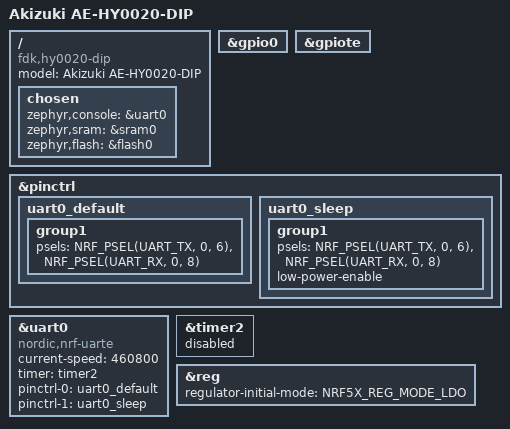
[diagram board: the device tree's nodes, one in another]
/dts-v1/;
#include <nordic/nrf52832_ciaa.dtsi>
#include <zephyr/dt-bindings/pinctrl/nrf-pinctrl.h>

/ {
    model = "Akizuki AE-HY0020-DIP";
    compatible = "fdk,hy0020-dip";

    chosen {
        zephyr,console = &uart0;
        zephyr,sram = &sram0;
        zephyr,flash = &flash0;
    };
};

&gpio0 {
    status = "okay";
};

&gpiote {
    status = "okay";
};

&pinctrl {
    uart0_default: uart0_default {
        group1 {
            psels = <NRF_PSEL(UART_TX, 0, 6)>, <NRF_PSEL(UART_RX, 0, 8)>;
        };
    };
    uart0_sleep: uart0_sleep {
        group1 {
            psels = <NRF_PSEL(UART_TX, 0, 6)>, <NRF_PSEL(UART_RX, 0, 8)>;
            low-power-enable;
        };
    };
};

&uart0 {
    status = "okay";
    compatible = "nordic,nrf-uarte";
    current-speed = <460800>;
    timer = <&timer2>;
    pinctrl-0 = <&uart0_default>;
    pinctrl-1 = <&uart0_sleep>;
    pinctrl-names = "default", "sleep";
};

/* UARTE RX byte counter; TIMER0 is reserved by the Bluetooth controller/MPSL. */
&timer2 {
    status = "reserved";
};

/* HY0020 carrier's DC/DC wiring is not assumed; keep LDO mode. */
&reg {
    regulator-initial-mode = <NRF5X_REG_MODE_LDO>;
};
